# nrf9120 register map
Vendor: Nordic Semiconductor; Series: nrf91; File version: 1
CPU: CM33 r0p4, little endian, MPU, FPU, 3 interrupt priority bits, 69 interrupts
Registers are 32-bit, read-write, reset 0x0 unless marked. A register's access mark holds for its fields unless they carry their own. Offsets are from the block's base; [hi:lo] are bit positions; lines under a group give offsets from that group; {n}, {i} and the like mark numbered series.

## FICR_S — Factory Information Configuration Registers
Base 0x00FF0000
0x200 INFO group — Device info
  {0x4+4j} DEVICEID[{j}] (j=0..1) ro reset 0xFFFFFFFF — Description collection: Device identifier
    [31:0] DEVICEID — 64 bit unique device identifier
  0x0C PART ro reset 0xFFFFFFFF — Part code
    [31:0] PART
      0x9161=N9161 (nRF9161); 0x9160=N9160 (nRF9160); 0x9151=N9151 (nRF9151); 0x9131=N9131 (nRF9131); 0x9120=N9120 (nRF9120)
  0x10 VARIANT ro reset 0xFFFFFFF — Part Variant, Hardware version and Production configuration
    [31:0] VARIANT — Part Variant, Hardware version and Production configuration, encoded as ASCII
      0x41414141=AAAA; 0x41414130=AAA0; 0x41414230=AAB0; 0x41414330=AAC0
  0x14 PACKAGE ro reset 0x2000 — Package option
    [31:0] PACKAGE
      0x2002=CECF (CExx or CFxx - 236 ball WLCSP)
  0x18 RAM ro reset 0x100 — RAM variant
    [31:0] RAM
      0x100=K256 (256 kByte RAM); 0xFFFFFFFF=Unspecified
  0x1C FLASH ro reset 0x400 — Flash variant
    [31:0] FLASH
      0x400=K1024 (1 MByte FLASH)
  0x20 CODEPAGESIZE ro reset 0x1000 — Code memory page size
    [31:0] CODEPAGESIZE
      0x1000=K4096 (4 kByte)
  0x24 CODESIZE ro reset 0x100 — Code memory size
    [31:0] CODESIZE — Code memory size in number of pages Total code space is: CODEPAGESIZE * CODESIZE
      0x100=P256 (256 pages)
  0x28 DEVICETYPE ro reset 0xFFFFFFFF
    [31:0] DEVICETYPE
      0=Die (Device is an physical DIE); 0xFFFFFFFF=FPGA (Device is an FPGA)
{0x300+8i} TRIMCNF[{i}] (i=0..255) group — Unspecified
  0x00 ADDR ro reset 0xFFFFFFFF — Description cluster: Address
    [31:0] Address
  0x04 DATA ro reset 0xFFFFFFFF — Description cluster: Data
0xC00 TRNG90B group — NIST800-90B RNG calibration data
  0x00 BYTES ro reset 0xFFFFFFFF — Amount of bytes for the required entropy bits
  0x04 RCCUTOFF ro reset 0xFFFFFFFF — Repetition counter cutoff
  0x08 APCUTOFF ro reset 0xFFFFFFFF — Adaptive proportion cutoff
  0x0C STARTUP ro reset 0xFFFFFFFF — Amount of bytes for the startup tests
  {0xC+4j} ROSC{j} ro reset 0xFFFFFFFF (j=1..4) — Sample count for ring oscillator configuration {j}

## TAD_S — Trace and debug control
Base 0xE0080000
0x00 TASKS_CLOCKSTART wo — Start all trace and debug clocks.
  [0] TASKS_CLOCKSTART
    1=Trigger task
0x04 TASKS_CLOCKSTOP wo — Stop all trace and debug clocks.
  [0] TASKS_CLOCKSTOP
    1=Trigger task
0x500 ENABLE — Enable debug domain and aquire selected GPIOs
  [0] ENABLE
    0=DISABLED (Disable debug domain and release selected GPIOs); 1=ENABLED (Enable debug domain and aquire selected GPIOs)
0x504 PSEL group — Unspecified
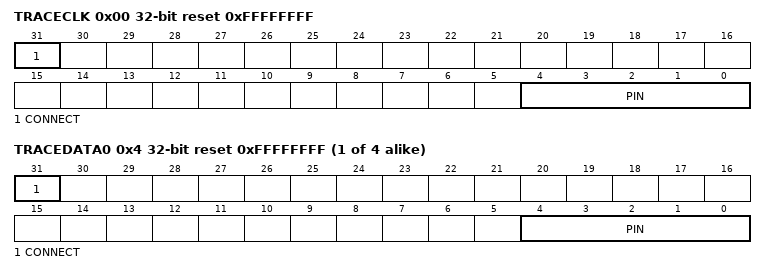
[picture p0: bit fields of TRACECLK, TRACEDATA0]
  0x00 TRACECLK reset 0xFFFFFFFF — Pin configuration for TRACECLK
    [31] CONNECT — Connection
      1=Disconnected; 0=Connected
    [4:0] PIN — Pin number
      21=TRACECLK pin
  {0x4+4j} TRACEDATA{j} reset 0xFFFFFFFF (j=0..3) — Pin configuration for TRACEDATA[{j}]
    [31] CONNECT — Connection
      1=Disconnected; 0=Connected
    [4:0] PIN — Pin number
      {j+22}=TRACEDATA{j} pin
0x518 TRACEPORTSPEED — Clocking options for the Trace Port debug interface Reset behavior is the same as debug components
  [1:0] TRACEPORTSPEED — Speed of Trace Port clock. Note that the TRACECLK pin output will be divided again by two from the Trace Port clock.
    0=32MHz (Trace Port clock is: 32MHz); 1=16MHz (Trace Port clock is: 16MHz); 2=8MHz (Trace Port clock is: 8MHz); 3=4MHz (Trace Port clock is: 4MHz)

## REGULATORS_NS — Voltage regulators control 0
Base 0x40004000
Same registers: REGULATORS_S 0x50004000
0x500 SYSTEMOFF wo
  [0] SYSTEMOFF — Enable System OFF mode
    1=Enable System OFF mode
0x514 EXTPOFCON — External power failure warning configuration
  [0] POF — Enable or disable external power failure warning
    0=Disabled; 1=Enabled
0x578 DCDCEN — Enable a step-down DC/DC voltage regulator.
  [0] DCDCEN — Enable DC/DC buck regulator
    0=Disabled (DC/DC buck regulator is disabled); 1=Enabled (DC/DC buck regulator is enabled)
